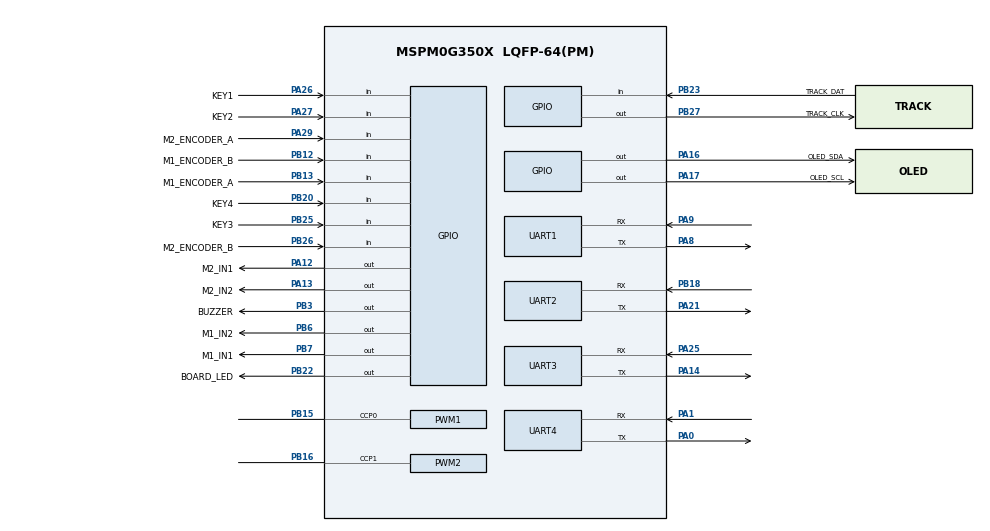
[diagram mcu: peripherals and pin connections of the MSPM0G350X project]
/**
 * Re-run the CLI after future pin changes so pinmux conflicts are reported.
 *
 * @cliArgs --device "MSPM0G350X" --part "Default" --package "LQFP-64(PM)" --product "mspm0_sdk@2.10.00.04"
 * @versions {"tool":"1.28.0+4712"}
 */

const Board         = scripting.addModule("/ti/driverlib/Board");
const GPIO          = scripting.addModule("/ti/driverlib/GPIO", {}, false);
const GPIO1         = GPIO.addInstance();
const GPIO2         = GPIO.addInstance();
const PWM           = scripting.addModule("/ti/driverlib/PWM", {}, false);
const PWM1          = PWM.addInstance();
const PWM2          = PWM.addInstance();
const SYSCTL        = scripting.addModule("/ti/driverlib/SYSCTL");
const UART          = scripting.addModule("/ti/driverlib/UART", {}, false);
const UART1         = UART.addInstance();
const UART2         = UART.addInstance();
const UART3         = UART.addInstance();
const UART4         = UART.addInstance();
const ProjectConfig = scripting.addModule("/ti/project_config/ProjectConfig");

const divider6       = system.clockTree["PLL_CLK2X_DIV"];
divider6.divideValue = 4;

const divider7       = system.clockTree["PLL_PDIV"];
divider7.divideValue = 2;

const divider9       = system.clockTree["UDIV"];
divider9.divideValue = 2;

const multiplier2         = system.clockTree["PLL_QDIV"];
multiplier2.multiplyValue = 10;

const mux8       = system.clockTree["HSCLKMUX"];
mux8.inputSelect = "HSCLKMUX_SYSPLL2X";

const mfclkGate  = system.clockTree["MFCLKGATE"];
mfclkGate.enable = true;

GPIO1.$name                               = "PORTB";
GPIO1.port                                = "PORTB";
GPIO1.associatedPins.create(11);
GPIO1.associatedPins[0].$name             = "TRACK_CLK";
GPIO1.associatedPins[0].assignedPin       = "27";
GPIO1.associatedPins[0].pin.$assign       = "PB27";
GPIO1.associatedPins[1].$name             = "TRACK_DAT";
GPIO1.associatedPins[1].assignedPin       = "23";
GPIO1.associatedPins[1].direction         = "INPUT";
GPIO1.associatedPins[1].pin.$assign       = "PB23";
GPIO1.associatedPins[2].$name             = "M1_IN2";
GPIO1.associatedPins[2].assignedPin       = "6";
GPIO1.associatedPins[2].pin.$assign       = "PB6";
GPIO1.associatedPins[3].$name             = "M1_IN1";
GPIO1.associatedPins[3].assignedPin       = "7";
GPIO1.associatedPins[3].pin.$assign       = "PB7";
GPIO1.associatedPins[4].$name             = "M1_ENCODER_A";
GPIO1.associatedPins[4].assignedPin       = "13";
GPIO1.associatedPins[4].direction         = "INPUT";
GPIO1.associatedPins[4].internalResistor  = "PULL_UP";
GPIO1.associatedPins[4].interruptEn       = true;
GPIO1.associatedPins[4].polarity          = "RISE_FALL";
GPIO1.associatedPins[4].pin.$assign       = "PB13";
GPIO1.associatedPins[5].$name             = "M1_ENCODER_B";
GPIO1.associatedPins[5].assignedPin       = "12";
GPIO1.associatedPins[5].direction         = "INPUT";
GPIO1.associatedPins[5].internalResistor  = "PULL_UP";
GPIO1.associatedPins[5].interruptEn       = true;
GPIO1.associatedPins[5].polarity          = "RISE_FALL";
GPIO1.associatedPins[5].pin.$assign       = "PB12";
GPIO1.associatedPins[6].$name             = "M2_ENCODER_B";
GPIO1.associatedPins[6].assignedPin       = "26";
GPIO1.associatedPins[6].direction         = "INPUT";
GPIO1.associatedPins[6].internalResistor  = "PULL_UP";
GPIO1.associatedPins[6].interruptEn       = true;
GPIO1.associatedPins[6].polarity          = "RISE_FALL";
GPIO1.associatedPins[6].pin.$assign       = "PB26";
GPIO1.associatedPins[7].$name             = "BUZZER";
GPIO1.associatedPins[7].assignedPin       = "3";
GPIO1.associatedPins[7].pin.$assign       = "PB3";
GPIO1.associatedPins[8].$name             = "KEY3";
GPIO1.associatedPins[8].assignedPin       = "25";
GPIO1.associatedPins[8].direction         = "INPUT";
GPIO1.associatedPins[8].internalResistor  = "PULL_UP";
GPIO1.associatedPins[8].pin.$assign       = "PB25";
GPIO1.associatedPins[9].$name             = "KEY4";
GPIO1.associatedPins[9].assignedPin       = "20";
GPIO1.associatedPins[9].direction         = "INPUT";
GPIO1.associatedPins[9].internalResistor  = "PULL_UP";
GPIO1.associatedPins[9].pin.$assign       = "PB20";
GPIO1.associatedPins[10].$name            = "BOARD_LED";
GPIO1.associatedPins[10].assignedPin      = "22";
GPIO1.associatedPins[10].internalResistor = "PULL_DOWN";
GPIO1.associatedPins[10].pin.$assign      = "PB22";

GPIO2.$name                              = "PORTA";
GPIO2.port                               = "PORTA";
GPIO2.associatedPins.create(7);
GPIO2.associatedPins[0].$name            = "M2_IN1";
GPIO2.associatedPins[0].assignedPin      = "12";
GPIO2.associatedPins[0].pin.$assign      = "PA12";
GPIO2.associatedPins[1].$name            = "M2_IN2";
GPIO2.associatedPins[1].assignedPin      = "13";
GPIO2.associatedPins[1].pin.$assign      = "PA13";
GPIO2.associatedPins[2].$name            = "M2_ENCODER_A";
GPIO2.associatedPins[2].assignedPin      = "29";
GPIO2.associatedPins[2].direction        = "INPUT";
GPIO2.associatedPins[2].internalResistor = "PULL_UP";
GPIO2.associatedPins[2].interruptEn      = true;
GPIO2.associatedPins[2].polarity         = "RISE_FALL";
GPIO2.associatedPins[2].pin.$assign      = "PA29";
GPIO2.associatedPins[3].$name            = "KEY1";
GPIO2.associatedPins[3].assignedPin      = "26";
GPIO2.associatedPins[3].direction        = "INPUT";
GPIO2.associatedPins[3].internalResistor = "PULL_UP";
GPIO2.associatedPins[3].pin.$assign      = "PA26";
GPIO2.associatedPins[4].$name            = "KEY2";
GPIO2.associatedPins[4].assignedPin      = "27";
GPIO2.associatedPins[4].direction        = "INPUT";
GPIO2.associatedPins[4].internalResistor = "PULL_UP";
GPIO2.associatedPins[4].pin.$assign      = "PA27";
GPIO2.associatedPins[5].$name            = "OLED_SDA";
GPIO2.associatedPins[5].assignedPin      = "16";
GPIO2.associatedPins[5].pin.$assign      = "PA16";
GPIO2.associatedPins[6].$name            = "OLED_SCL";
GPIO2.associatedPins[6].assignedPin      = "17";
GPIO2.associatedPins[6].pin.$assign      = "PA17";

PWM1.$name                      = "Motor_PWM1";
PWM1.timerStartTimer            = true;
PWM1.pwmMode                    = "EDGE_ALIGN_UP";
PWM1.timerCount                 = 3000;
PWM1.clockDivider               = 8;
PWM1.ccIndex                    = [0];
PWM1.peripheral.$assign         = "TIMG7";
PWM1.peripheral.ccp0Pin.$assign = "PB15";
PWM1.PWM_CHANNEL_0.$name        = "M1_PWMA";
PWM1.PWM_CHANNEL_0.dutyCycle    = 0;

PWM2.$name                      = "Motor_PWM2";
PWM2.timerStartTimer            = true;
PWM2.pwmMode                    = "EDGE_ALIGN_UP";
PWM2.timerCount                 = 3000;
PWM2.clockDivider               = 4;
PWM2.ccIndex                    = [1];
PWM2.peripheral.$assign         = "TIMG8";
PWM2.peripheral.ccp1Pin.$assign = "PB16";
PWM2.PWM_CHANNEL_1.$name        = "M2_PWMB";
PWM2.PWM_CHANNEL_1.dutyCycle    = 0;

SYSCTL.MFCLKEn     = true;
SYSCTL.clockTreeEn = true;

UART1.$name                    = "GYRO_UART";
UART1.targetBaudRate           = 115200;
UART1.uartClkSrc               = "MFCLK";
UART1.rxFifoThreshold          = "DL_UART_RX_FIFO_LEVEL_ONE_ENTRY";
UART1.enableDMARX              = false;
UART1.enableDMATX              = false;
UART1.enabledInterrupts        = ["RX"];
UART1.peripheral.$assign       = "UART1";
UART1.peripheral.txPin.$assign = "PA8";
UART1.peripheral.rxPin.$assign = "PA9";

UART2.$name                    = "CAM_UART";
UART2.targetBaudRate           = 115200;
UART2.enabledInterrupts        = ["RX"];
UART2.peripheral.$assign       = "UART2";
UART2.peripheral.txPin.$assign = "PA21";
UART2.peripheral.rxPin.$assign = "PB18";

UART3.$name                    = "DEBUG_UART";
UART3.targetBaudRate           = 115200;
UART3.peripheral.$assign       = "UART3";
UART3.peripheral.txPin.$assign = "PA14";
UART3.peripheral.rxPin.$assign = "PA25";

UART4.$name                    = "GIMBAL_UART";
UART4.targetBaudRate           = 115200;
UART4.peripheral.$assign       = "UART0";
UART4.peripheral.txPin.$assign = "PA0";
UART4.peripheral.rxPin.$assign = "PA1";

ProjectConfig.genDisable = true;
scripting.suppress("Project Configuration File generation is disabled for this project\\. SysConfig Project Migration is not currently supported for this project\\.", ProjectConfig);

Board.peripheral.$suggestSolution          = "DEBUGSS";
Board.peripheral.swclkPin.$suggestSolution = "PA20";
Board.peripheral.swdioPin.$suggestSolution = "PA19";
